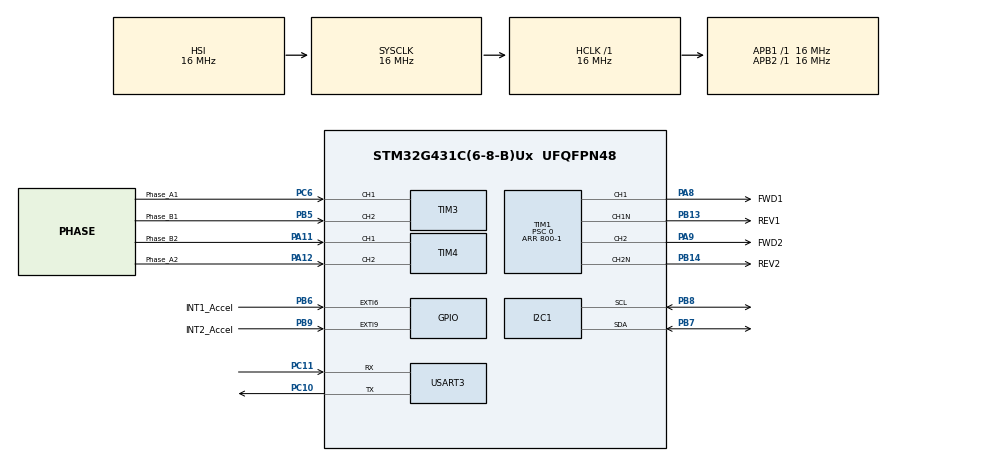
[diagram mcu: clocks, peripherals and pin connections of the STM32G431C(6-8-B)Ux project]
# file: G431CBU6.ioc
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I2C1.Timing=0x00503D58
Mcu.Family=STM32G4
Mcu.Name=STM32G431C(6-8-B)Ux
Mcu.Package=UFQFPN48
NVIC.EXTI9_5_IRQn=true\:0\:0\:false\:false\:true\:true\:true\:true
NVIC.PriorityGroup=NVIC_PRIORITYGROUP_4
PA11.GPIO_Label=Phase_B2
PA11.Signal=S_TIM4_CH1
PA12.GPIO_Label=Phase_A2
PA12.Signal=S_TIM4_CH2
PA13.Mode=Trace_Asynchronous_SW
PA13.Signal=SYS_JTMS-SWDIO
PA14.Mode=Trace_Asynchronous_SW
PA14.Signal=SYS_JTCK-SWCLK
PA8.GPIO_Label=FWD1
PA8.Signal=S_TIM1_CH1
PA9.GPIO_Label=FWD2
PA9.Signal=S_TIM1_CH2
PB13.GPIO_Label=REV1
PB13.Mode=PWM Generation1 CH1 CH1N
PB13.Signal=TIM1_CH1N
PB14.GPIO_Label=REV2
PB14.Mode=PWM Generation2 CH2 CH2N
PB14.Signal=TIM1_CH2N
PB3.Mode=Trace_Asynchronous_SW
PB3.Signal=SYS_JTDO-SWO
PB5.GPIO_Label=Phase_B1
PB5.Signal=S_TIM3_CH2
PB6.GPIO_Label=INT1_Accel
PB6.Signal=GPXTI6
PB7.Mode=I2C
PB7.Signal=I2C1_SDA
PB8-BOOT0.Mode=I2C
PB8-BOOT0.Signal=I2C1_SCL
PB9.GPIO_Label=INT2_Accel
PB9.Signal=GPXTI9
PC10.Mode=Asynchronous
PC10.Signal=USART3_TX
PC11.Mode=Asynchronous
PC11.Signal=USART3_RX
PC6.GPIO_Label=Phase_A1
PC6.Signal=S_TIM3_CH1
ProjectManager.HeapSize=0x200
ProjectManager.StackSize=0x400
ProjectManager.TargetToolchain=CMake
RCC.AHBFreq_Value=16000000
RCC.APB1Freq_Value=16000000
RCC.APB1TimFreq_Value=16000000
RCC.APB2Freq_Value=16000000
RCC.APB2TimFreq_Value=16000000
RCC.CortexFreq_Value=16000000
RCC.EXTERNAL_CLOCK_VALUE=12288000
RCC.HCLKFreq_Value=16000000
RCC.HSE_VALUE=8000000
RCC.HSI48_VALUE=48000000
RCC.HSI_VALUE=16000000
RCC.LSE_VALUE=32768
RCC.SYSCLKFreq_VALUE=16000000
RCC.USBFreq_Value=64000000
RCC.VCOOutputFreq_Value=128000000
SH.S_TIM1_CH1.0=TIM1_CH1,PWM Generation1 CH1 CH1N
SH.S_TIM1_CH2.0=TIM1_CH2,PWM Generation2 CH2 CH2N
SH.S_TIM3_CH1.0=TIM3_CH1,Encoder_Interface
SH.S_TIM3_CH2.0=TIM3_CH2,Encoder_Interface
SH.S_TIM4_CH1.0=TIM4_CH1,Encoder_Interface
SH.S_TIM4_CH2.0=TIM4_CH2,Encoder_Interface
TIM1.Channel-PWM\ Generation1\ CH1\ CH1N=TIM_CHANNEL_1
TIM1.Channel-PWM\ Generation2\ CH2\ CH2N=TIM_CHANNEL_2
TIM1.PeriodNoDither=800-1
TIM1.Prescaler=0
USART3.VirtualMode-Asynchronous=VM_ASYNC
VP_SYS_VS_DBSignals.Mode=DisableDeadBatterySignals
VP_TIM1_VS_ClockSourceINT.Mode=Internal
board=custom

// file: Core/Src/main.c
/* USER CODE BEGIN Header */
/**
  ******************************************************************************
  * @file           : main.c
  * @brief          : Main program body
  ******************************************************************************
  * @attention
  *
  * Copyright (c) 2025 STMicroelectronics.
  * All rights reserved.
  *
  * This software is licensed under terms that can be found in the LICENSE file
  * in the root directory of this software component.
  * If no LICENSE file comes with this software, it is provided AS-IS.
  *
  ******************************************************************************
  */
/* USER CODE END Header */
#include "main.h"
#include "i2c.h"
#include "tim.h"
#include "usart.h"
#include "gpio.h"

/* USER CODE BEGIN Includes */
#include "motors.h"
#include <stdio.h>
/* USER CODE END Includes */

void SystemClock_Config(void);

/* USER CODE BEGIN 0 */

int __io_putchar(int ch){
    HAL_UART_Transmit(&huart3, (uint8_t*)&ch, 1, HAL_MAX_DELAY);
    return ch;
}
/* USER CODE END 0 */

int main(void)
{

  /* MCU Configuration--------------------------------------------------------*/

  /* Reset of all peripherals, Initializes the Flash interface and the Systick. */
  HAL_Init();

  /* Configure the system clock */
  SystemClock_Config();

  /* Initialize all configured peripherals */
  MX_GPIO_Init();
  MX_TIM1_Init();
  MX_TIM3_Init();
  MX_TIM4_Init();
  MX_USART3_UART_Init();
  MX_I2C1_Init();
  /* USER CODE BEGIN 2 */
  printf("BONJOUR LE MONDE\r\n");
  motors_init();

  /* USER CODE END 2 */

  /* Infinite loop */
  /* USER CODE BEGIN WHILE */
  while (1)
  {
    motor_forward(60, 'R');
    motor_forward(20, 'L');
    HAL_Delay(5000);
    motor_backward(40, 'R');
    motor_backward(80,'L');
    HAL_Delay(3000);

    /* USER CODE END WHILE */

  }
}

void SystemClock_Config(void)
{
  RCC_OscInitTypeDef RCC_OscInitStruct = {0};
  RCC_ClkInitTypeDef RCC_ClkInitStruct = {0};

  /** Configure the main internal regulator output voltage
  */
  HAL_PWREx_ControlVoltageScaling(PWR_REGULATOR_VOLTAGE_SCALE1);

  /** Initializes the RCC Oscillators according to the specified parameters
  * in the RCC_OscInitTypeDef structure.
  */
  RCC_OscInitStruct.OscillatorType = RCC_OSCILLATORTYPE_HSI;
  RCC_OscInitStruct.HSIState = RCC_HSI_ON;
  RCC_OscInitStruct.HSICalibrationValue = RCC_HSICALIBRATION_DEFAULT;
  RCC_OscInitStruct.PLL.PLLState = RCC_PLL_NONE;
  if (HAL_RCC_OscConfig(&RCC_OscInitStruct) != HAL_OK)
  {
    Error_Handler();
  }

  /** Initializes the CPU, AHB and APB buses clocks
  */
  RCC_ClkInitStruct.ClockType = RCC_CLOCKTYPE_HCLK|RCC_CLOCKTYPE_SYSCLK
                              |RCC_CLOCKTYPE_PCLK1|RCC_CLOCKTYPE_PCLK2;
  RCC_ClkInitStruct.SYSCLKSource = RCC_SYSCLKSOURCE_HSI;
  RCC_ClkInitStruct.AHBCLKDivider = RCC_SYSCLK_DIV1;
  RCC_ClkInitStruct.APB1CLKDivider = RCC_HCLK_DIV1;
  RCC_ClkInitStruct.APB2CLKDivider = RCC_HCLK_DIV1;

  if (HAL_RCC_ClockConfig(&RCC_ClkInitStruct, FLASH_LATENCY_0) != HAL_OK)
  {
    Error_Handler();
  }
}

void Error_Handler(void)
{
  __disable_irq();
  while (1)
  {
  }
}
